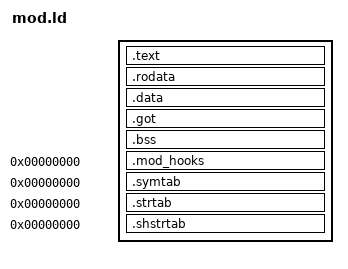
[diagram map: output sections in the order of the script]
/* A mod's link: generated by recomp --mod-api; do not edit.
 *
 * The image goes at MOD_ORIGIN (mods/build.sh --origin; the mod region's
 * base by default) and must end before the region's guard word and stack.
 * .mod_hooks is not loaded: the runtime reads it from the ELF. Each game
 * function is a symbol at its address, and mod_call_original is the
 * runtime's. */

ENTRY(mod_entry_none)
mod_entry_none = 0;

mod_call_original = 0x1f3ffff0;
ov_a_80100004 = 0x80100004;
a_fn = 0x80100004;
ov_b_80100004 = 0x80100004;
b_fn = 0x80100004;
ov_b_80100010 = 0x80100010;
ram_80010000 = 0x80010000;
entry_alias = 0x80010000;
start = 0x80010000;
ram_80010008 = 0x80010008;
ram_80010010 = 0x80010010;
ram_80010020 = 0x80010020;
ram_80010030 = 0x80010030;
ram_80010040 = 0x80010040;
ram_80010050 = 0x80010050;
ram_800100f0 = 0x800100f0;
last = 0x800100f0;

mod_origin = DEFINED(MOD_ORIGIN) ? MOD_ORIGIN : 0x1f400000;

SECTIONS {
	. = mod_origin;
	.text : { *(.text .text.*) }
	.rodata : { *(.rodata .rodata.*) }
	.data : { *(.data .data.* .sdata .sdata.*) }
	.got : { *(.got) }
	.bss : { *(.bss .bss.* .sbss .sbss.* COMMON) }
	mod_end = .;
	.mod_hooks 0 (INFO) : { KEEP(*(.mod_hooks)) }
	.symtab 0 : { *(.symtab) }
	.strtab 0 : { *(.strtab) }
	.shstrtab 0 : { *(.shstrtab) }
	/DISCARD/ : { *(.eh_frame*) *(.MIPS.*) *(.reginfo) *(.pdr) *(.comment) *(.gnu.attributes) *(.mdebug.*) }
}

/* build.sh links with --orphan-handling=error: every loaded section is one
 * of the above, so mod_end is the image's end. */
ASSERT(mod_origin >= 0x1f400000 && mod_origin < 0x1f7fbff0, "mod: the origin is outside the mod region")
ASSERT(mod_origin % 16 == 0, "mod: the origin is not 16-byte aligned")
ASSERT(mod_end <= 0x1f7fbff0, "mod: the image runs past the mod region (its stack and guard)")
